# aes: IP-XACT component
VLNV tenstorrent.com:ocah:aes:1.0

## Address spaces and blocks
aes_mmap.aes: base 'h0, range 'h8c, width 32

## Registers
Registers are 32-bit, write-only, reset 0x0 unless marked. A register's access mark holds for its fields unless they carry their own. Offsets are from the block's base; lines under a group give offsets from that group; [hi:lo] are bit positions; {n}, {i} and the like mark numbered series; 'fields as' and 'values as' point back to an identical list; <NAME> marks a mode.

## aes_mmap.aes — AES encryption and decryption engine with SCA and FI countermeasures
Base 0x00000000
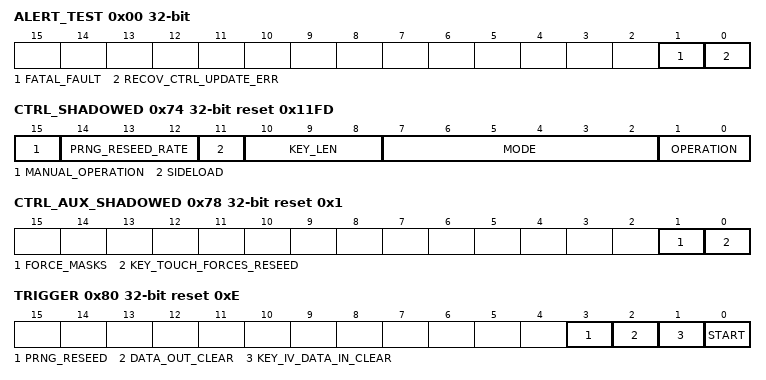
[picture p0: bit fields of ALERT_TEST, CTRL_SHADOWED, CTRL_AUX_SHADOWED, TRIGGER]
0x00 ALERT_TEST
  [1] FATAL_FAULT — Write 1 to trigger one alert event of this kind.
  [0] RECOV_CTRL_UPDATE_ERR — Write 1 to trigger one alert event of this kind.
{0x4+4i} KEY_SHARE0[{i}] (i=0..7)
  [31:0] KEY_SHARE0 — Initial Key Share 0
{0x24+4i} KEY_SHARE1[{i}] (i=0..7)
  [31:0] KEY_SHARE1 — Initial Key Share 1
{0x44+4i} IV[{i}] (i=0..3) rw
  [31:0] IV — Initialization Vector
{0x54+4i} DATA_IN[{i}] (i=0..3)
  [31:0] DATA_IN — Input Data
{0x64+4i} DATA_OUT[{i}] (i=0..3) ro
  [31:0] DATA_OUT — Output Data
0x74 CTRL_SHADOWED rw reset 0x11FD
  [15] MANUAL_OPERATION — Controls whether the AES unit is operated in normal/automatic mode (0) or fully manual mode (1). In automatic mode (0), the AES unit automatically i) starts to encrypt/decrypt when it receives new input data, and ii) stalls during the last encryption/decryption cycle if the previous output data has not yet been read. This is the most efficient mode to operate in. Note that the corresponding status tracking is automatically cleared upon a write to the Control Register. In manual mode (1), the AES unit i) only starts to encrypt/decrypt after receiving a start trigger (see Trigger Register), and ii) overwrites previous output data irrespective of whether it has been read out or not. This mode is useful if software needs full control over the AES unit.
  [14:12] PRNG_RESEED_RATE — 3-bit one-hot field to control the reseeding rate of the internal pseudo-random number generator (PRNG) used for masking. Invalid input values, i.e., values with multiple bits set and value 3'b000 are mapped to the highest reseeding rate PER_1 (3'b001).
  [11] SIDELOAD — Controls whether the AES unit uses the key provided by the key manager via key sideload interface (1) or the key provided by software via Initial Key Registers KEY_SHARE1_0 - KEY_SHARE1_7 (0).
  [10:8] KEY_LEN — 3-bit one-hot field to select AES key length. Invalid input values, i.e., values with multiple bits set, value 3'b000, and value 3'b010 in case 192-bit keys are not supported (because disabled at compile time) are mapped to AES_256 (3'b100).
  [7:2] MODE — 6-bit one-hot field to select AES block cipher mode. Invalid input values, i.e., values with multiple bits set and value 6'b00_0000, are mapped to AES_NONE (6'b11_1111).
  [1:0] OPERATION — 2-bit one-hot field to select the operation of AES unit. Invalid input values, i.e., values with multiple bits set and value 2'b00, are mapped to AES_ENC (2'b01).
0x78 CTRL_AUX_SHADOWED rw reset 0x1
  [1] FORCE_MASKS — Allow the internal masking PRNG to advance (0) or force its internal state (1) leading to constant masks. Setting all masks to constant value can be useful when performing SCA. To completely disable the masking, the second key share (KEY_SHARE1_0 - KEY_SHARE1_7) must be zero as well. In addition, a special seed needs to be loaded into the masking PRNG using the EDN interface. Only applicable if both the Masking parameter and the SecAllowForcingMasks parameter are set to one.
  [0] KEY_TOUCH_FORCES_RESEED — Controls whether providing a new key triggers the reseeding of internal pseudo-random number generators used for clearing and masking (1) or not (0).
0x7C CTRL_AUX_REGWEN rw reset 0x1
  [0] CTRL_AUX_REGWEN write-0-clears — Auxiliary Control Register configuration enable bit. If this is cleared to 0, the Auxiliary Control Register cannot be written anymore.
0x80 TRIGGER reset 0xE
  [3] PRNG_RESEED — Keep continuing with the current states of the internal pseudo-random number generators used for register clearing and masking (0) or perform a reseed of the internal states from the connected entropy source (1). If the KEY_TOUCH_FORCES_RESEED bit in the Auxiliary Control Register is set to one, this trigger will automatically get set after providing a new initial key.
  [2] DATA_OUT_CLEAR — Keep current values in Output Data registers (0) or clear those registers with pseudo-random data (1).
  [1] KEY_IV_DATA_IN_CLEAR — Keep current values in Initial Key, internal Full Key and Decryption Key registers, IV registers and Input Data registers (0) or clear all those registers with pseudo-random data (1).
  [0] START — Keep AES unit paused (0) or trigger the encryption/decryption of one data block (1). This trigger is cleared to `0` if MANUAL_OPERATION=0 or if MODE=AES_NONE (see Control Register).
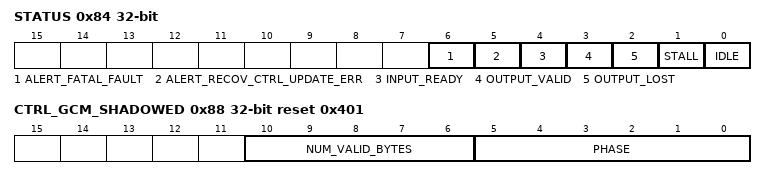
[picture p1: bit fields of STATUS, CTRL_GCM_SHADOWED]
0x84 STATUS ro
  [6] ALERT_FATAL_FAULT — No fatal fault has occurred inside the AES unit (0). A fatal fault has occurred and the AES unit needs to be reset (1). Examples for fatal faults include i) storage errors in the Control Register, ii) if any internal FSM enters an invalid state, iii) if any sparsely encoded signal takes on an invalid value, iv) errors in the internal round counter, v) escalations triggered by the life cycle controller, and vi) fatal integrity failures on the TL-UL bus.
  [5] ALERT_RECOV_CTRL_UPDATE_ERR — An update error has not occurred (0) or has occurred (1) in the shadowed Control Register. AES operation needs to be restarted by re-writing the Control Register.
  [4] INPUT_READY — The AES unit is ready (1) or not ready (0) to receive new data input via the DATA_IN registers. If the present values in the DATA_IN registers have not yet been loaded into the module this flag is `0` (not ready).
  [3] OUTPUT_VALID — The AES unit has no valid output (0) or has valid output data (1).
  [2] OUTPUT_LOST — All previous output data has been fully read by the processor (0) or at least one previous output data block has been lost (1). It has been overwritten by the AES unit before the processor could fully read it. Once set to `1`, this flag remains set until AES operation is restarted by re-writing the Control Register. The primary use of this flag is for design verification. This flag is not meaningful if MANUAL_OPERATION=0 (see Control Register).
  [1] STALL — The AES unit is not stalled (0) or stalled (1) because there is previous output data that must be read by the processor before the AES unit can overwrite this data. This flag is not meaningful if MANUAL_OPERATION=1 (see Control Register).
  [0] IDLE — The AES unit is idle (1) or busy (0). This flag is `0` if one of the following operations is currently running: i) encryption/decryption, ii) register clearing or iii) PRNG reseeding. This flag is also `0` if an encryption/decryption is running but the AES unit is stalled.
0x88 CTRL_GCM_SHADOWED rw reset 0x401
  [10:6] NUM_VALID_BYTES — Number of valid bytes of the current input block. Only the last block in the GCM_AAD and GCM_TEXT phases are expected to have not all bytes marked as valid. For all other blocks, the number of valid bytes should be set to 16. Invalid input values, i.e., the value 5'b0_0000, and all other values different from 5'b1_0000 in case GCM is not supported (because disabled at compile time) are mapped to 5'b1_0000.
  [5:0] PHASE — 6-bit one-hot field to select the phase of the Galois/Counter Mode (GCM) of operation. Invalid input values, i.e., values with multiple bits set and value 6'b00_0000, are mapped to GCM_INIT (6'b00_0001). In case support for GCM has been disabled at compile time, this field is not writable and always reads as GCM_INIT (6'b00_0001).

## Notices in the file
SPDX-License-Identifier: Apache-2.0
SPDX-FileCopyrightText: 2026 Tenstorrent USA, Inc.
